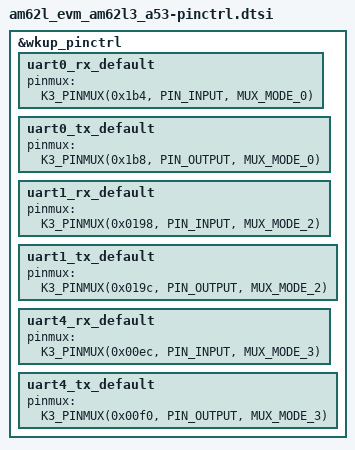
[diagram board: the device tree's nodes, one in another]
/*
 * Copyright (C) 2025 Texas Instruments Incorporated - https://www.ti.com/
 *
 * SPDX-License-Identifier: Apache-2.0
 */

&wkup_pinctrl {
	status = "okay";

	uart0_rx_default: uart0_rx_default {
		pinmux = <K3_PINMUX(0x1b4, PIN_INPUT, MUX_MODE_0)>; /* (D13) UART0_RXD */
	};

	uart0_tx_default: uart0_tx_default {
		pinmux = <K3_PINMUX(0x1b8, PIN_OUTPUT, MUX_MODE_0)>; /* (C13) UART0_TXD */
	};

	uart1_rx_default: uart1_rx_default {
		/* (C11) MCASP0_AFSR.UART1_RXD */
		pinmux = <K3_PINMUX(0x0198, PIN_INPUT, MUX_MODE_2)>;
	};

	uart1_tx_default: uart1_tx_default {
		/* (A12) MCASP0_ACLKR.UART1_TXD */
		pinmux = <K3_PINMUX(0x019c, PIN_OUTPUT, MUX_MODE_2)>;
	};

	uart4_rx_default: uart4_rx_default {
		pinmux = <K3_PINMUX(0x00ec, PIN_INPUT, MUX_MODE_3)>; /* (M23) GPMC0_CSn2.UART4_RXD */
	};

	uart4_tx_default: uart4_tx_default {
		pinmux = <K3_PINMUX(0x00f0, PIN_OUTPUT, MUX_MODE_3)>; /* (M22) GPMC0_CSn3.UART4_TXD */
	};	
};
